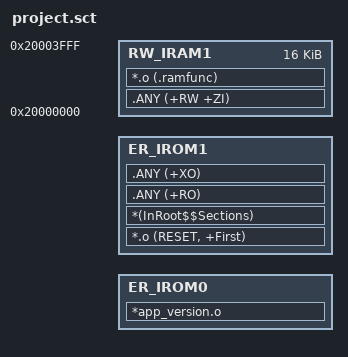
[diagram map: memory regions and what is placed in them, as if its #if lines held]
#! armcc -E
; *************************************************************
; *** Scatter-Loading Description File generated by uVision ***
; *************************************************************

#include "..\include\image_map_config.h"


LR_IROM1 APP_IMAGE_START APP_IMAGE_SIZE  {    ; load region size_region
  #if SIZE_IMAGE_HEADER
	ER_IROM0 APP_IMAGE_START SIZE_IMAGE_HEADER  {  ; load address = execution address
   *app_version.o
  }
  #endif
  ER_IROM1 (APP_IMAGE_START + SIZE_IMAGE_HEADER) APP_IMAGE_SIZE  {  ; load address = execution address
   *.o (RESET, +First)
   *(InRoot$$Sections)
   .ANY (+RO)
   .ANY (+XO)
  }
  RW_IRAM1 0x20000000 0x00004000  {  ; RW data
   .ANY (+RW +ZI)
   *.o (.ramfunc)
  }
}

